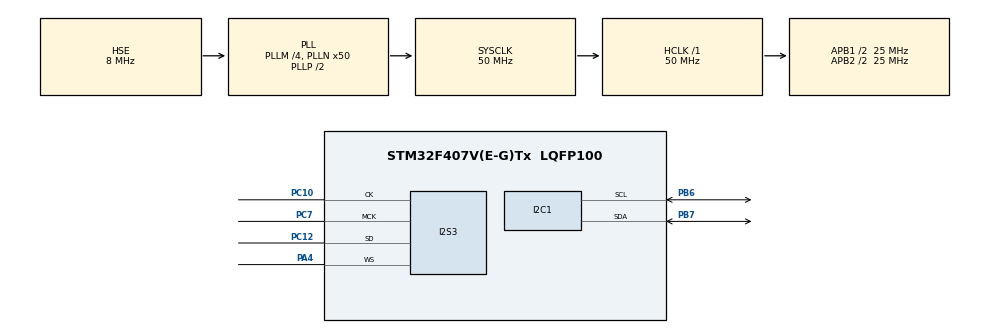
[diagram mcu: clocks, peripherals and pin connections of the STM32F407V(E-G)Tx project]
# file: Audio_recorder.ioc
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Dma.Request0=SPI3_RX
Dma.SPI3_RX.0.Direction=DMA_PERIPH_TO_MEMORY
Dma.SPI3_RX.0.FIFOMode=DMA_FIFOMODE_DISABLE
Dma.SPI3_RX.0.Instance=DMA1_Stream0
Dma.SPI3_RX.0.MemDataAlignment=DMA_MDATAALIGN_HALFWORD
Dma.SPI3_RX.0.MemInc=DMA_MINC_ENABLE
Dma.SPI3_RX.0.Mode=DMA_CIRCULAR
Dma.SPI3_RX.0.PeriphDataAlignment=DMA_PDATAALIGN_HALFWORD
Dma.SPI3_RX.0.PeriphInc=DMA_PINC_DISABLE
Dma.SPI3_RX.0.Priority=DMA_PRIORITY_LOW
I2S3.DataFormat=I2S_DATAFORMAT_16B_EXTENDED
I2S3.ErrorAudioFreq=1.72 %
I2S3.FullDuplexMode=I2S_FULLDUPLEXMODE_DISABLE
I2S3.Instance=SPI$Index
I2S3.Mode=I2S_MODE_MASTER_RX
I2S3.RealAudioFreq=8.138 KHz
I2S3.VirtualMode=I2S_MODE_MASTER
Mcu.Family=STM32F4
Mcu.Name=STM32F407V(E-G)Tx
Mcu.Package=LQFP100
NVIC.DMA1_Stream0_IRQn=true\:0\:0\:false\:false\:true\:false\:true\:true
NVIC.PriorityGroup=NVIC_PRIORITYGROUP_0
PA4.Mode=Half_Duplex_Master
PA4.Signal=I2S3_WS
PB6.Mode=I2C
PB6.Signal=I2C1_SCL
PB7.Mode=I2C
PB7.Signal=I2C1_SDA
PC10.Mode=Half_Duplex_Master
PC10.Signal=I2S3_CK
PC12.Mode=Half_Duplex_Master
PC12.Signal=I2S3_SD
PC7.Mode=Master_Clock_Activated
PC7.Signal=I2S3_MCK
PH0-OSC_IN.Mode=HSE-External-Oscillator
PH0-OSC_IN.Signal=RCC_OSC_IN
PH1-OSC_OUT.Mode=HSE-External-Oscillator
PH1-OSC_OUT.Signal=RCC_OSC_OUT
ProjectManager.HeapSize=0x200
ProjectManager.StackSize=0x400
ProjectManager.TargetToolchain=STM32CubeIDE
RCC.48MHZClocksFreq_Value=14285714.285714285
RCC.AHBFreq_Value=50000000
RCC.APB1CLKDivider=RCC_HCLK_DIV2
RCC.APB1Freq_Value=25000000
RCC.APB1TimFreq_Value=50000000
RCC.APB2CLKDivider=RCC_HCLK_DIV2
RCC.APB2Freq_Value=25000000
RCC.APB2TimFreq_Value=50000000
RCC.CortexFreq_Value=50000000
RCC.HCLKFreq_Value=50000000
RCC.HSE_VALUE=8000000
RCC.HSI_VALUE=16000000
RCC.LSE_VALUE=32768
RCC.PLLI2SN=50
RCC.PLLM=4
RCC.PLLN=50
RCC.PLLQ=7
RCC.PLLSourceVirtual=RCC_PLLSOURCE_HSE
RCC.SYSCLKFreq_VALUE=50000000
RCC.SYSCLKSource=RCC_SYSCLKSOURCE_PLLCLK
RCC.VCOOutputFreq_Value=100000000
board=STM32F407G-DISC1

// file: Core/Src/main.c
/* USER CODE BEGIN Header */
/**
  ******************************************************************************
  * @file           : main.c
  * @brief          : Main program body
  ******************************************************************************
  * @attention
  *
  * Copyright (c) 2023 STMicroelectronics.
  * All rights reserved.
  *
  * This software is licensed under terms that can be found in the LICENSE file
  * in the root directory of this software component.
  * If no LICENSE file comes with this software, it is provided AS-IS.
  *
  ******************************************************************************
  */
/* USER CODE END Header */
#include "main.h"

I2C_HandleTypeDef hi2c1;

I2S_HandleTypeDef hi2s3;
DMA_HandleTypeDef hdma_spi3_rx;

void SystemClock_Config(void);
static void MX_GPIO_Init(void);
static void MX_DMA_Init(void);
static void MX_I2C1_Init(void);
static void MX_I2S3_Init(void);
/* USER CODE BEGIN PFP */
/*Application ProgrammingInterface:API
 * low level func:enabling clock, gpio peripgheral etc.
 * high level func:determining the how to receive and transmit data as functions
 */
/* USER CODE END PFP */

int main(void)
{

  /* MCU Configuration--------------------------------------------------------*/

  /* Reset of all peripherals, Initializes the Flash interface and the Systick. */
  HAL_Init();

  /* Configure the system clock */
  SystemClock_Config();

  /* Initialize all configured peripherals */
  MX_GPIO_Init();
  MX_DMA_Init();
  MX_I2C1_Init();
  MX_I2S3_Init();

  /* Infinite loop */
  while (1)
  {

  }
}

void SystemClock_Config(void)
{
  RCC_OscInitTypeDef RCC_OscInitStruct = {0};
  RCC_ClkInitTypeDef RCC_ClkInitStruct = {0};

  /** Configure the main internal regulator output voltage
  */
  __HAL_RCC_PWR_CLK_ENABLE();
  __HAL_PWR_VOLTAGESCALING_CONFIG(PWR_REGULATOR_VOLTAGE_SCALE1);

  /** Initializes the RCC Oscillators according to the specified parameters
  * in the RCC_OscInitTypeDef structure.
  */
  RCC_OscInitStruct.OscillatorType = RCC_OSCILLATORTYPE_HSE;
  RCC_OscInitStruct.HSEState = RCC_HSE_ON;
  RCC_OscInitStruct.PLL.PLLState = RCC_PLL_ON;
  RCC_OscInitStruct.PLL.PLLSource = RCC_PLLSOURCE_HSE;
  RCC_OscInitStruct.PLL.PLLM = 4;
  RCC_OscInitStruct.PLL.PLLN = 50;
  RCC_OscInitStruct.PLL.PLLP = RCC_PLLP_DIV2;
  RCC_OscInitStruct.PLL.PLLQ = 7;
  if (HAL_RCC_OscConfig(&RCC_OscInitStruct) != HAL_OK)
  {
    Error_Handler();
  }

  /** Initializes the CPU, AHB and APB buses clocks
  */
  RCC_ClkInitStruct.ClockType = RCC_CLOCKTYPE_HCLK|RCC_CLOCKTYPE_SYSCLK
                              |RCC_CLOCKTYPE_PCLK1|RCC_CLOCKTYPE_PCLK2;
  RCC_ClkInitStruct.SYSCLKSource = RCC_SYSCLKSOURCE_PLLCLK;
  RCC_ClkInitStruct.AHBCLKDivider = RCC_SYSCLK_DIV1;
  RCC_ClkInitStruct.APB1CLKDivider = RCC_HCLK_DIV2;
  RCC_ClkInitStruct.APB2CLKDivider = RCC_HCLK_DIV2;

  if (HAL_RCC_ClockConfig(&RCC_ClkInitStruct, FLASH_LATENCY_1) != HAL_OK)
  {
    Error_Handler();
  }
}

static void MX_I2C1_Init(void)
{

  hi2c1.Instance = I2C1;
  hi2c1.Init.ClockSpeed = 100000;
  hi2c1.Init.DutyCycle = I2C_DUTYCYCLE_2;
  hi2c1.Init.OwnAddress1 = 0;
  hi2c1.Init.AddressingMode = I2C_ADDRESSINGMODE_7BIT;
  hi2c1.Init.DualAddressMode = I2C_DUALADDRESS_DISABLE;
  hi2c1.Init.OwnAddress2 = 0;
  hi2c1.Init.GeneralCallMode = I2C_GENERALCALL_DISABLE;
  hi2c1.Init.NoStretchMode = I2C_NOSTRETCH_DISABLE;
  if (HAL_I2C_Init(&hi2c1) != HAL_OK)
  {
    Error_Handler();
  }

}

static void MX_I2S3_Init(void)
{

  hi2s3.Instance = SPI3;
  hi2s3.Init.Mode = I2S_MODE_MASTER_RX;
  hi2s3.Init.Standard = I2S_STANDARD_PHILIPS;
  hi2s3.Init.DataFormat = I2S_DATAFORMAT_16B_EXTENDED;
  hi2s3.Init.MCLKOutput = I2S_MCLKOUTPUT_ENABLE;
  hi2s3.Init.AudioFreq = I2S_AUDIOFREQ_8K;
  hi2s3.Init.CPOL = I2S_CPOL_LOW;
  hi2s3.Init.ClockSource = I2S_CLOCK_PLL;
  hi2s3.Init.FullDuplexMode = I2S_FULLDUPLEXMODE_DISABLE;
  if (HAL_I2S_Init(&hi2s3) != HAL_OK)
  {
    Error_Handler();
  }

}

static void MX_DMA_Init(void)
{

  /* DMA controller clock enable */
  __HAL_RCC_DMA1_CLK_ENABLE();

  /* DMA interrupt init */
  /* DMA1_Stream0_IRQn interrupt configuration */
  HAL_NVIC_SetPriority(DMA1_Stream0_IRQn, 0, 0);
  HAL_NVIC_EnableIRQ(DMA1_Stream0_IRQn);

}

static void MX_GPIO_Init(void)
{

  /* GPIO Ports Clock Enable */
  __HAL_RCC_GPIOH_CLK_ENABLE();
  __HAL_RCC_GPIOA_CLK_ENABLE();
  __HAL_RCC_GPIOC_CLK_ENABLE();
  __HAL_RCC_GPIOB_CLK_ENABLE();

}

void Error_Handler(void)
{
  __disable_irq();
  while (1)
  {
  }
}
